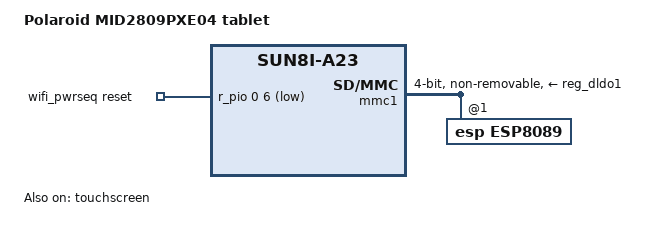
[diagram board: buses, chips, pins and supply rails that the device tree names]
/*
 * Copyright 2016 Hans de Goede <hdegoede@redhat.com>
 *
 * This file is dual-licensed: you can use it either under the terms
 * of the GPL or the X11 license, at your option. Note that this dual
 * licensing only applies to this file, and not this project as a
 * whole.
 *
 *  a) This file is free software; you can redistribute it and/or
 *     modify it under the terms of the GNU General Public License as
 *     published by the Free Software Foundation; either version 2 of the
 *     License, or (at your option) any later version.
 *
 *     This file is distributed in the hope that it will be useful,
 *     but WITHOUT ANY WARRANTY; without even the implied warranty of
 *     MERCHANTABILITY or FITNESS FOR A PARTICULAR PURPOSE.  See the
 *     GNU General Public License for more details.
 *
 * Or, alternatively,
 *
 *  b) Permission is hereby granted, free of charge, to any person
 *     obtaining a copy of this software and associated documentation
 *     files (the "Software"), to deal in the Software without
 *     restriction, including without limitation the rights to use,
 *     copy, modify, merge, publish, distribute, sublicense, and/or
 *     sell copies of the Software, and to permit persons to whom the
 *     Software is furnished to do so, subject to the following
 *     conditions:
 *
 *     The above copyright notice and this permission notice shall be
 *     included in all copies or substantial portions of the Software.
 *
 *     THE SOFTWARE IS PROVIDED "AS IS", WITHOUT WARRANTY OF ANY KIND,
 *     EXPRESS OR IMPLIED, INCLUDING BUT NOT LIMITED TO THE WARRANTIES
 *     OF MERCHANTABILITY, FITNESS FOR A PARTICULAR PURPOSE AND
 *     NONINFRINGEMENT. IN NO EVENT SHALL THE AUTHORS OR COPYRIGHT
 *     HOLDERS BE LIABLE FOR ANY CLAIM, DAMAGES OR OTHER LIABILITY,
 *     WHETHER IN AN ACTION OF CONTRACT, TORT OR OTHERWISE, ARISING
 *     FROM, OUT OF OR IN CONNECTION WITH THE SOFTWARE OR THE USE OR
 *     OTHER DEALINGS IN THE SOFTWARE.
 */

/dts-v1/;
#include "sun8i-a23.dtsi"
#include "sun8i-reference-design-tablet.dtsi"

/ {
	model = "Polaroid MID2809PXE04 tablet";
	compatible = "polaroid,mid2809pxe04", "allwinner,sun8i-a23";

	aliases {
		ethernet0 = &esp8089;
	};

	wifi_pwrseq: pwrseq {
		compatible = "mmc-pwrseq-simple";
		reset-gpios = <&r_pio 0 6 GPIO_ACTIVE_LOW>; /* PL6 */
		/* The esp8089 needs 200 ms after driving wifi-en high */
		post-power-on-delay-ms = <200>;
	};
};

&mmc1 {
	pinctrl-names = "default";
	pinctrl-0 = <&mmc1_pg_pins>;
	vmmc-supply = <&reg_dldo1>;
	mmc-pwrseq = <&wifi_pwrseq>;
	bus-width = <4>;
	non-removable;
	status = "okay";

	esp8089: wifi@1 {
		compatible = "esp,esp8089";
		reg = <1>;
		esp,crystal-26M-en = <2>;
	};
};

&touchscreen {
	reg = <0x40>;
	compatible = "silead,gsl3670";
	firmware-name = "gsl3670-polaroid-mid2809pxe04.fw";
	touchscreen-size-x = <1660>;
	touchscreen-size-y = <890>;
	status = "okay";
};
